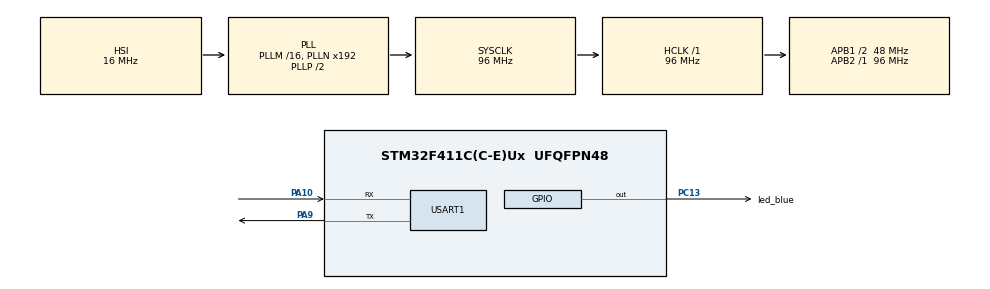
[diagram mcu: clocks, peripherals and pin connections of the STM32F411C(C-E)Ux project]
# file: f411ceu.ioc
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FREERTOS.Tasks01=defaultTask,24,128,StartDefaultTask,Default,NULL,Dynamic,NULL,NULL;userTask,8,1024,userTaskCb,Default,NULL,Dynamic,NULL,NULL
Mcu.Family=STM32F4
Mcu.Name=STM32F411C(C-E)Ux
Mcu.Package=UFQFPN48
NVIC.PriorityGroup=NVIC_PRIORITYGROUP_4
PA10.Mode=Asynchronous
PA10.Signal=USART1_RX
PA9.Mode=Asynchronous
PA9.Signal=USART1_TX
PC13-ANTI_TAMP.GPIO_Label=led_blue
PC13-ANTI_TAMP.PinState=GPIO_PIN_SET
PC13-ANTI_TAMP.Signal=GPIO_Output
ProjectManager.HeapSize=0x200
ProjectManager.StackSize=0x400
ProjectManager.TargetToolchain=MDK-ARM V5.27
RCC.AHBFreq_Value=96000000
RCC.APB1CLKDivider=RCC_HCLK_DIV2
RCC.APB1Freq_Value=48000000
RCC.APB1TimFreq_Value=96000000
RCC.APB2Freq_Value=96000000
RCC.APB2TimFreq_Value=96000000
RCC.CortexFreq_Value=96000000
RCC.HCLKFreq_Value=96000000
RCC.HSE_VALUE=25000000
RCC.HSI_VALUE=16000000
RCC.LSE_VALUE=32768
RCC.SYSCLKFreq_VALUE=96000000
RCC.SYSCLKSource=RCC_SYSCLKSOURCE_PLLCLK
RCC.VCOOutputFreq_Value=192000000
USART1.VirtualMode=VM_ASYNC
VP_FREERTOS_VS_CMSIS_V2.Mode=CMSIS_V2
board=custom

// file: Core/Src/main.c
/* USER CODE BEGIN Header */
/**
 ******************************************************************************
 * @file           : main.c
 * @brief          : Main program body
 ******************************************************************************
 * @attention
 *
 * <h2><center>&copy; Copyright (c) 2025 STMicroelectronics.
 * All rights reserved.</center></h2>
 *
 * This software component is licensed by ST under Ultimate Liberty license
 * SLA0044, the "License"; You may not use this file except in compliance with
 * the License. You may obtain a copy of the License at:
 *                             www.st.com/SLA0044
 *
 ******************************************************************************
 */
/* USER CODE END Header */
#include "main.h"
#include "cmsis_os.h"
#include "stdint.h"
#include "stdio.h"
#include "string.h"
#include "stdarg.h"
/* USER CODE BEGIN Includes */
// #include "core_armv8mml.h"
/* USER CODE END Includes */

UART_HandleTypeDef huart1;

/* Definitions for defaultTask */
osThreadId_t defaultTaskHandle;
const osThreadAttr_t defaultTask_attributes = {
    .name = "defaultTask",
    .priority = (osPriority_t)osPriorityNormal,
    .stack_size = 128 * 4};
/* Definitions for userTask */
osThreadId_t userTaskHandle;
const osThreadAttr_t userTask_attributes = {
    .name = "userTask",
    .priority = (osPriority_t)osPriorityLow,
    .stack_size = 1024 * 4};

void SystemClock_Config(void);
static void MX_GPIO_Init(void);
static void MX_USART1_UART_Init(void);
void StartDefaultTask(void *argument);
void userTaskCb(void *argument);

/* USER CODE BEGIN PFP */

#ifdef __GNUC__
  /* With GCC, small printf (option LD Linker->Libraries->Small printf
     set to 'Yes') calls __io_putchar() */
  #define PUTCHAR_PROTOTYPE int __io_putchar(int ch)
#else
  #define PUTCHAR_PROTOTYPE int fputc(int ch, FILE *f)
#endif /* __GNUC__ */

/**
  * @brief  Retargets the C library printf function to the USART.
  * @param  None
  * @retval None
  */
PUTCHAR_PROTOTYPE
{
  /* Place your implementation of fputc here */
  /* e.g. write a character to the USART1 and Loop until the end of transmission */
  HAL_UART_Transmit(&huart1, (uint8_t *)&ch, 1, HAL_MAX_DELAY);
  return ch;
}

/* USER CODE END PFP */

int main(void)
{

  /* MCU Configuration--------------------------------------------------------*/

  /* Reset of all peripherals, Initializes the Flash interface and the Systick. */
  HAL_Init();

  /* Configure the system clock */
  SystemClock_Config();

  /* Initialize all configured peripherals */
  MX_GPIO_Init();
  MX_USART1_UART_Init();
  /* USER CODE BEGIN 2 */
  volatile uint32_t freq=HAL_RCC_GetSysClockFreq();
  printf("System Clock Frequency: %u Hz\n", freq);
  /* USER CODE END 2 */

  /* Init scheduler */
  osKernelInitialize();

  /* Create the thread(s) */
  /* creation of defaultTask */
  defaultTaskHandle = osThreadNew(StartDefaultTask, NULL, &defaultTask_attributes);

  /* creation of userTask */
  userTaskHandle = osThreadNew(userTaskCb, NULL, &userTask_attributes);

  /* Start scheduler */
  osKernelStart();

  /* We should never get here as control is now taken by the scheduler */
  /* Infinite loop */
  while (1)
  {

  }
}

void SystemClock_Config(void)
{
  RCC_OscInitTypeDef RCC_OscInitStruct = {0};
  RCC_ClkInitTypeDef RCC_ClkInitStruct = {0};

  /** Configure the main internal regulator output voltage
   */
  __HAL_RCC_PWR_CLK_ENABLE();
  __HAL_PWR_VOLTAGESCALING_CONFIG(PWR_REGULATOR_VOLTAGE_SCALE1);
  /** Initializes the RCC Oscillators according to the specified parameters
   * in the RCC_OscInitTypeDef structure.
   */
  RCC_OscInitStruct.OscillatorType = RCC_OSCILLATORTYPE_HSI;
  RCC_OscInitStruct.HSIState = RCC_HSI_ON;
  RCC_OscInitStruct.HSICalibrationValue = RCC_HSICALIBRATION_DEFAULT;
  RCC_OscInitStruct.PLL.PLLState = RCC_PLL_ON;
  RCC_OscInitStruct.PLL.PLLSource = RCC_PLLSOURCE_HSI;
  RCC_OscInitStruct.PLL.PLLM = 16;
  RCC_OscInitStruct.PLL.PLLN = 192;
  RCC_OscInitStruct.PLL.PLLP = RCC_PLLP_DIV2;
  RCC_OscInitStruct.PLL.PLLQ = 4;
  if (HAL_RCC_OscConfig(&RCC_OscInitStruct) != HAL_OK)
  {
    Error_Handler();
  }
  /** Initializes the CPU, AHB and APB buses clocks
   */
  RCC_ClkInitStruct.ClockType = RCC_CLOCKTYPE_HCLK | RCC_CLOCKTYPE_SYSCLK | RCC_CLOCKTYPE_PCLK1 | RCC_CLOCKTYPE_PCLK2;
  RCC_ClkInitStruct.SYSCLKSource = RCC_SYSCLKSOURCE_PLLCLK;
  RCC_ClkInitStruct.AHBCLKDivider = RCC_SYSCLK_DIV1;
  RCC_ClkInitStruct.APB1CLKDivider = RCC_HCLK_DIV2;
  RCC_ClkInitStruct.APB2CLKDivider = RCC_HCLK_DIV1;

  if (HAL_RCC_ClockConfig(&RCC_ClkInitStruct, FLASH_LATENCY_3) != HAL_OK)
  {
    Error_Handler();
  }
}

static void MX_USART1_UART_Init(void)
{

  huart1.Instance = USART1;
  huart1.Init.BaudRate = 115200;
  huart1.Init.WordLength = UART_WORDLENGTH_8B;
  huart1.Init.StopBits = UART_STOPBITS_1;
  huart1.Init.Parity = UART_PARITY_NONE;
  huart1.Init.Mode = UART_MODE_TX_RX;
  huart1.Init.HwFlowCtl = UART_HWCONTROL_NONE;
  huart1.Init.OverSampling = UART_OVERSAMPLING_16;
  if (HAL_UART_Init(&huart1) != HAL_OK)
  {
    Error_Handler();
  }
}

static void MX_GPIO_Init(void)
{
  GPIO_InitTypeDef GPIO_InitStruct = {0};

  /* GPIO Ports Clock Enable */
  __HAL_RCC_GPIOC_CLK_ENABLE();
  __HAL_RCC_GPIOA_CLK_ENABLE();

  /*Configure GPIO pin Output Level */
  HAL_GPIO_WritePin(led_blue_GPIO_Port, led_blue_Pin, GPIO_PIN_SET);

  /*Configure GPIO pin : led_blue_Pin */
  GPIO_InitStruct.Pin = led_blue_Pin;
  GPIO_InitStruct.Mode = GPIO_MODE_OUTPUT_PP;
  GPIO_InitStruct.Pull = GPIO_NOPULL;
  GPIO_InitStruct.Speed = GPIO_SPEED_FREQ_LOW;
  HAL_GPIO_Init(led_blue_GPIO_Port, &GPIO_InitStruct);
}

#define LED_BLUE_ON() HAL_GPIO_WritePin(led_blue_GPIO_Port, led_blue_Pin, GPIO_PIN_RESET)
#define LED_BLUE_OFF() HAL_GPIO_WritePin(led_blue_GPIO_Port, led_blue_Pin, GPIO_PIN_SET)
#define LED_BLUE_TOGGLE() HAL_GPIO_TogglePin(led_blue_GPIO_Port, led_blue_Pin)

void StartDefaultTask(void *argument)
{
  /* USER CODE BEGIN 5 */
  /* Infinite loop */
  for (;;)
  {
    LED_BLUE_TOGGLE();
    osDelay(1000);
  }
  /* USER CODE END 5 */
}

void userTaskCb(void *argument)
{
  /* USER CODE BEGIN userTaskCb */
  /* Infinite loop */
  for (;;)
  {
    osDelay(1000);
    printf("Hello World!\r\n");
  }
  /* USER CODE END userTaskCb */
}

void Error_Handler(void)
{
}

/************************ (C) COPYRIGHT STMicroelectronics *****END OF FILE****/
